# MCXN947_cm33_core0 register map
Vendor: nxp.com; File version: 1.0
CPU: CM33 r2p0, little endian, MPU, FPU, VTOR, 3 interrupt priority bits
Registers are 32-bit, read-write, reset 0x0 unless marked. A register's access mark holds for its fields unless they carry their own. Offsets are from the block's base; [hi:lo] are bit positions; {n}, {i} and the like mark numbered series.

## USBHS1__USBC — USB
Base 0x4010B000
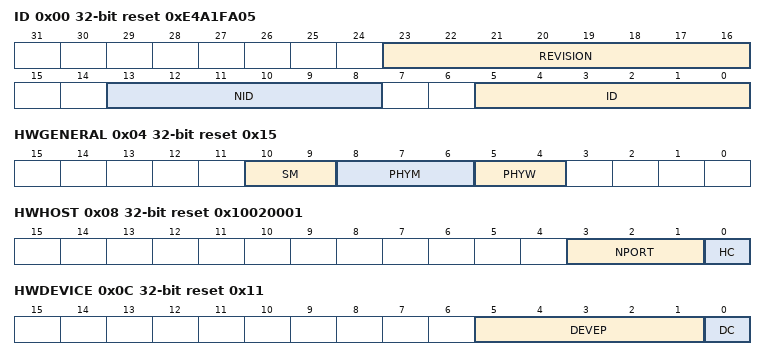
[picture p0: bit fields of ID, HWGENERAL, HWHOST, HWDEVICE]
0x00 ID ro reset 0xE4A1FA05 — Identification register
  [23:16] REVISION, [13:8] NID, [5:0] ID
0x04 HWGENERAL ro reset 0x15 — Hardware General
  [10:9] SM
    0=SERIAL_ENGINE_NO (No Serial Engine, always use parallel signalling.); 1=SERIAL_ENGINE_EN (Serial Engine present, always use serial signalling for FS/LS.); 2=SW_RST_PARALLEL (Software programmable - Reset to use parallel signalling for FS/LS); 3=SW_RST_SERIAL_ENG (Software programmable - Reset to use serial signalling for FS/LS)
  [8:6] PHYM
    0=UTMI (UTMI/UMTI+); 1=ULPI_DDR; 2=ULPI; 3=SERIAL (Serial Only); 4=SW_RST_UTMI (Software programmable - reset to UTMI/UTMI+); 5=SW_RST_ULPI_DDR (Software programmable - reset to ULPI DDR); 6=SW_RST_ULPI (Software programmable - reset to ULPI); 7=SW_RST_SERIAL (Software programmable - reset to Serial)
  [5:4] PHYW
    0=DATA_BUS_8 (8 bit wide data bus (Software non-programmable)); 1=DATA_BUS_16 (16 bit wide data bus (Software non-programmable)); 2=SW_RST_8 (Reset to 8 bit wide data bus (Software programmable)); 3=SW_RST_16 (Reset to 16 bit wide data bus (Software programmable))
0x08 HWHOST ro reset 0x10020001 — Host Hardware Parameters
  [3:1] NPORT
  [0] HC
    0=HOST_OP_DIS (Not supported); 1=HOST_OP_EN (Supported)
0x0C HWDEVICE ro reset 0x11 — Device Hardware Parameters
  [5:1] DEVEP
  [0] DC
    0=DEVICE_OP_DIS (Not supported); 1=DEVICE_OP_EN (Supported)
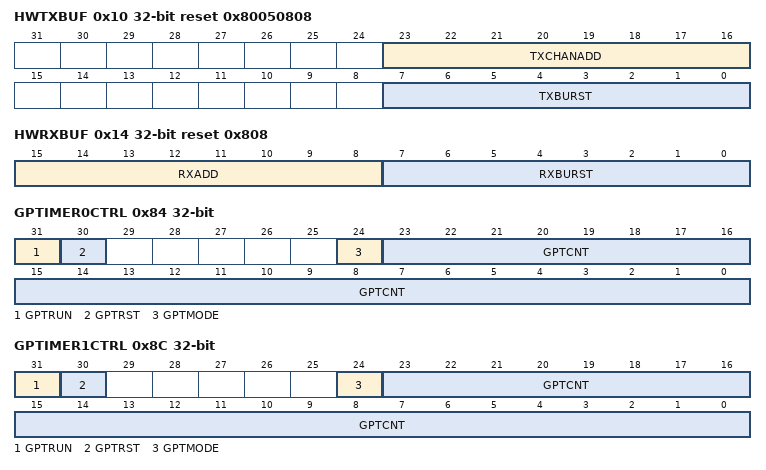
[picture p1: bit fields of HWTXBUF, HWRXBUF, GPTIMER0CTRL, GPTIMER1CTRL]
0x10 HWTXBUF ro reset 0x80050808 — TX Buffer Hardware Parameters
  [23:16] TXCHANADD, [7:0] TXBURST
0x14 HWRXBUF ro reset 0x808 — RX Buffer Hardware Parameters
  [15:8] RXADD, [7:0] RXBURST
0x80 GPTIMER0LD — General Purpose Timer #0 Load
  [23:0] GPTLD
0x84 GPTIMER0CTRL — General Purpose Timer #0 Controller
  [31] GPTRUN
    0=STOP_CNTR (Stop counting); 1=RUN
  [30] GPTRST wo
    0=NO_ACTION; 1=LOAD_CNTR (Load counter value from GPTLD bits in n_GPTIMER0LD)
  [24] GPTMODE
    0=ONE_SHOT (One Shot Mode); 1=REPEAT (Repeat Mode)
  [23:0] GPTCNT ro
0x88 GPTIMER1LD — General Purpose Timer #1 Load
  [23:0] GPTLD
0x8C GPTIMER1CTRL — General Purpose Timer #1 Controller
  [31] GPTRUN
    0=STOP_CNTR (Stop counting); 1=RUN
  [30] GPTRST wo
    0=NO_ACTION; 1=LOAD_CNTR (Load counter value from GPTLD bits in USB_n_GPTIMER0LD)
  [24] GPTMODE
    0=ONE_SHOT (One Shot Mode); 1=REPEAT (Repeat Mode)
  [23:0] GPTCNT ro
0x90 SBUSCFG reset 0x2 — System Bus Config
  [2:0] AHBBRST
    0=INCR_BURST (Incremental burst of unspecified length only); 1=INCR4_BURST (INCR4 burst, then single transfer); 2=INCR8_BURST (INCR8 burst, INCR4 burst, then single transfer); 3=INCR16_BURST (INCR16 burst, INCR8 burst, INCR4 burst, then single transfer); 5=INCR4_UNSPEC (INCR4 burst, then incremental burst of unspecified length); 6=INCR8_4_UNSPEC (INCR8 burst, INCR4 burst, then incremental burst of unspecified length); 7=INCR16_8_4_UNSPEC (INCR16 burst, INCR8 burst, INCR4 burst, then incremental burst of unspecified length)
0x100 CAPLENGTH 8-bit ro reset 0x40 — Capability Registers Length
0x102 HCIVERSION 16-bit ro reset 0x100 — Host Controller Interface Version
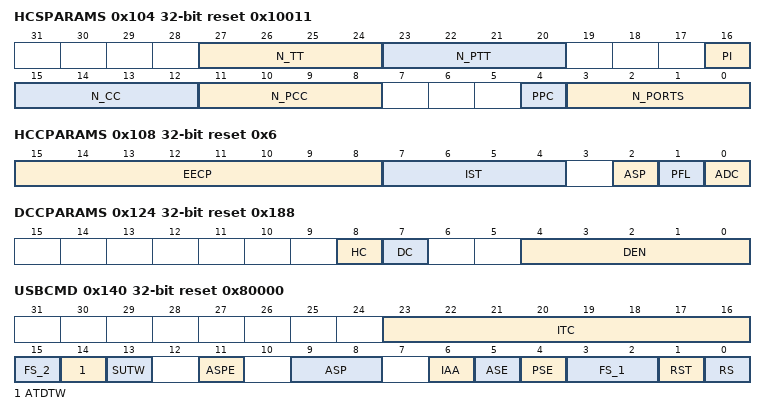
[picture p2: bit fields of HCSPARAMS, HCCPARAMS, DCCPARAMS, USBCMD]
0x104 HCSPARAMS ro reset 0x10011 — Host Controller Structural Parameters
  [27:24] N_TT
  [23:20] N_PTT
  [16] PI
  [15:12] N_CC
    0=NO_COMP_CONTROLLER (There is no internal Companion Controller and port-ownership hand-off is not supported.); 1=COMP_CONTROLLER (There are internal companion controller(s) and port-ownership hand-offs is supported.)
  [11:8] N_PCC
  [4] PPC
  [3:0] N_PORTS
0x108 HCCPARAMS ro reset 0x6 — Host Controller Capability Parameters
  [15:8] EECP, [7:4] IST, [2] ASP, [1] PFL, [0] ADC
0x120 DCIVERSION 16-bit ro reset 0x1 — Device Controller Interface Version
0x124 DCCPARAMS ro reset 0x188 — Device Controller Capability Parameters
  [8] HC, [7] DC, [4:0] DEN
0x140 USBCMD reset 0x80000 — USB Command Register
  [23:16] ITC
    0=IMMEDIATE (Immediate (no threshold)); 1=MICROFRAME_1 (1 micro-frame); 2=MICROFRAME_2 (2 micro-frames); 4=MICROFRAME_4 (4 micro-frames); 8=MICROFRAME_8 (8 micro-frames); 16=MICROFRAME_16 (16 micro-frames); 32=MICROFRAME_32 (32 micro-frames); 64=MICROFRAME_64 (64 micro-frames)
  [15] FS_2
  [14] ATDTW
  [13] SUTW
  [11] ASPE
  [9:8] ASP
  [6] IAA
  [5] ASE
    0=DONT_PROCESS_ASYNC (Do not process the Asynchronous Schedule.); 1=ACCESS_ASYNC (Use the ASYNCLISTADDR register to access the Asynchronous Schedule.)
  [4] PSE
    0=DONT_PROCESS_PT (Do not process the Periodic Schedule); 1=PROCESS_PT_PERIODICLISTBASE (Use the PERIODICLISTBASE register to access the Periodic Schedule.)
  [3:2] FS_1
  [1] RST
  [0] RS
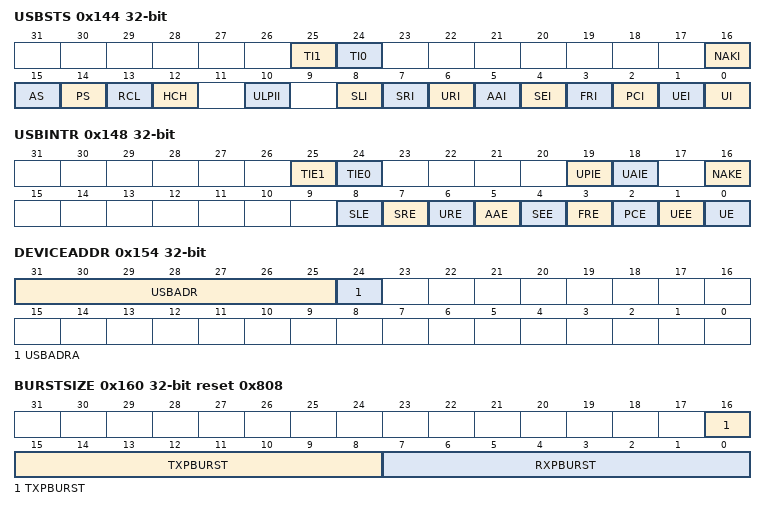
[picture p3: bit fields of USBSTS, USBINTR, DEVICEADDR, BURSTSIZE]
0x144 USBSTS (reset mask 0xFFFFFF7F) — USB Status Register
  [25] TI1 write-1-clears, [24] TI0 write-1-clears, [16] NAKI ro, [15] AS ro, [14] PS ro, [13] RCL ro, [12] HCH ro, [10] ULPII write-1-clears, [8] SLI write-1-clears, [7] SRI write-1-clears, [6] URI write-1-clears, [5] AAI write-1-clears, [4] SEI write-1-clears, [3] FRI write-1-clears, [2] PCI write-1-clears, [1] UEI write-1-clears, [0] UI write-1-clears
0x148 USBINTR — Interrupt Enable Register
  [25] TIE1, [24] TIE0, [19] UPIE, [18] UAIE, [16] NAKE, [8] SLE, [7] SRE, [6] URE, [5] AAE, [4] SEE, [3] FRE, [2] PCE, [1] UEE, [0] UE
0x14C FRINDEX — USB Frame Index
  [13:0] FRINDEX
    0=(1024) 12; 1=(512) 11; 2=(256) 10; 3=(128) 9; 4=(64) 8; 5=(32) 7; 6=(16) 6; 7=(8) 5
0x154 DEVICEADDR (ADDRESS_MODES view) — Device Address
  [31:25] USBADR, [24] USBADRA
0x154 PERIODICLISTBASE (ADDRESS_MODES view) — Frame List Base Address
  [31:12] BASEADR
0x158 ASYNCLISTADDR (ADDRESS_MODES view) — Next Asynch. Address
  [31:5] ASYBASE
0x158 ENDPTLISTADDR (ADDRESS_MODES view) — Endpoint List Address
  [31:11] EPBASE
0x160 BURSTSIZE reset 0x808 — Programmable Burst Size
  [16:8] TXPBURST, [7:0] RXPBURST
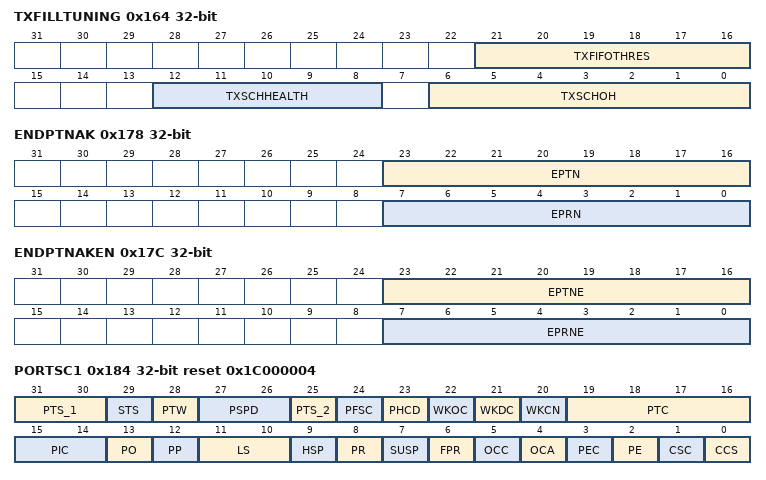
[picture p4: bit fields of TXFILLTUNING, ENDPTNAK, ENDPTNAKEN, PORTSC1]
0x164 TXFILLTUNING — TX FIFO Fill Tuning
  [21:16] TXFIFOTHRES, [12:8] TXSCHHEALTH, [6:0] TXSCHOH
0x178 ENDPTNAK write-1-clears — Endpoint NAK
  [23:16] EPTN write-1-clears, [7:0] EPRN write-1-clears
0x17C ENDPTNAKEN — Endpoint NAK Enable
  [23:16] EPTNE, [7:0] EPRNE
0x180 CONFIGFLAG ro reset 0x1 — Configure Flag Register
  [0] CF
    0=PORT_ROUTING_CLASSIC_HOST (Port routing control logic default-routes each port to an implementation dependent classic host controller.); 1=PORT_ROUTING_HOST (Port routing control logic default-routes all ports to this host controller.)
0x184 PORTSC1 reset 0x1C000004 — Port Status & Control
  [31:30] PTS_1 ro
  [29] STS ro
  [28] PTW ro
    0=UTMI_8 (Select the 8-bit UTMI interface [60MHz]); 1=UTMI_16 (Select the 16-bit UTMI interface [30MHz])
  [27:26] PSPD
    0=FS (Full Speed); 1=LS (Low Speed); 2=HS (High Speed); 3=UNDEFINED
  [25] PTS_2 ro
  [24] PFSC
    0=NORMAL (Normal operation); 1=FULL_SPEED (Forced to full speed)
  [23] PHCD
    0=PHY_CLK_EN (Enable PHY clock); 1=PHY_CLK_DIS (Disable PHY clock)
  [22] WKOC
  [21] WKDC
  [20] WKCN
  [19:16] PTC
    0=TST_MODE_DIS (TEST_MODE_DISABLE); 1=J_STATE; 2=K_STATE; 3=SE0 (SE0 (host) / NAK (device)); 4=PCKT (Packet); 5=HS (FORCE_ENABLE_HS); 6=FS (FORCE_ENABLE_FS); 7=LS (FORCE_ENABLE_LS)
  [15:14] PIC
    0=PORT_INDICATOR_OFF (Port indicators are off); 1=PORT_IND_AMBER (Amber); 2=PORT_IND_GREEN (Green); 3=UNDEFINED
  [13] PO ro
  [12] PP
  [11:10] LS ro
    0=SE0; 1=K_STATE; 2=J_STATE; 3=UNDEFINED
  [9] HSP ro
  [8] PR
  [7] SUSP
  [6] FPR
  [5] OCC write-1-clears
  [4] OCA ro
    0=NO_OVERCURRENT (This port does not have an over-current condition.); 1=OVERCURRENT (This port currently has an over-current condition)
  [3] PEC write-1-clears
  [2] PE
  [1] CSC write-1-clears
  [0] CCS ro
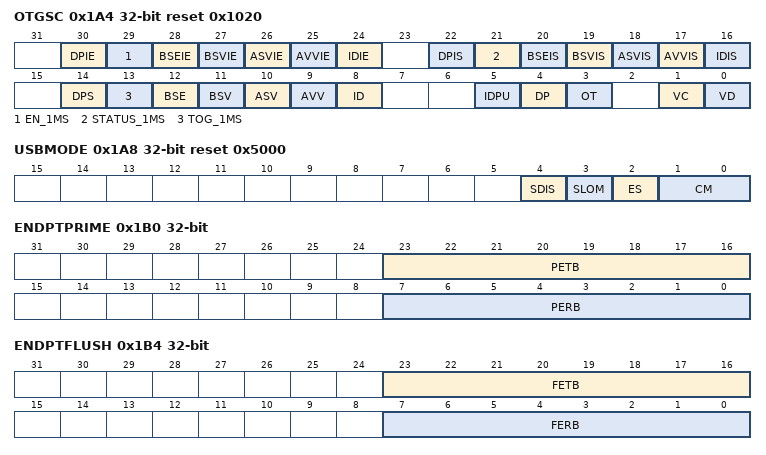
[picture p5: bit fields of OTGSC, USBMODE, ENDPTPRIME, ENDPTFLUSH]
0x1A4 OTGSC reset 0x1020 (reset mask 0xFFDFDDFF) — On-The-Go Status & control
  [30] DPIE, [29] EN_1MS, [28] BSEIE, [27] BSVIE, [26] ASVIE, [25] AVVIE, [24] IDIE, [22] DPIS, [21] STATUS_1MS, [20] BSEIS, [19] BSVIS, [18] ASVIS, [17] AVVIS, [16] IDIS, [14] DPS ro, [13] TOG_1MS ro, [12] BSE ro, [11] BSV ro, [10] ASV ro, [9] AVV ro, [8] ID ro, [5] IDPU, [4] DP, [3] OT, [1] VC, [0] VD
0x1A8 USBMODE reset 0x5000 — USB Device Mode
  [4] SDIS
  [3] SLOM
    0=LOCKOUT_ON (Setup Lockouts On (default);); 1=LOCKOUT_OFF (Setup Lockouts Off)
  [2] ES
    0=LITTLE_ENDIAN (Little Endian [Default]); 1=BIG_ENDIAN
  [1:0] CM
    0=IDL (Idle [Default for combination host/device]); 2=DEVICE_CONTR (Device Controller [Default for device only controller]); 3=HOST_CONTR (Host Controller [Default for host only controller])
0x1AC ENDPTSETUPSTAT write-1-clears — Endpoint Setup Status
  [15:0] ENDPTSETUPSTAT write-1-clears
0x1B0 ENDPTPRIME — Endpoint Prime
  [23:16] PETB, [7:0] PERB
0x1B4 ENDPTFLUSH — Endpoint Flush
  [23:16] FETB, [7:0] FERB
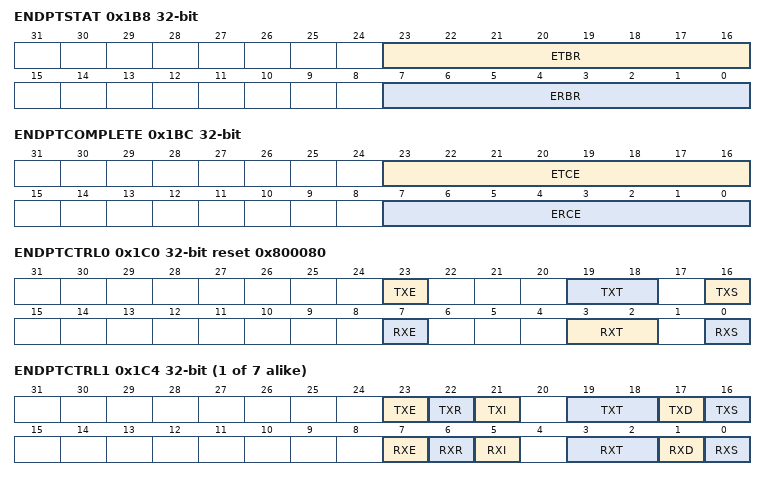
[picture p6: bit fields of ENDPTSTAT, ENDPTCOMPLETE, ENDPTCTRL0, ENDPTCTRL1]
0x1B8 ENDPTSTAT ro — Endpoint Status
  [23:16] ETBR, [7:0] ERBR
0x1BC ENDPTCOMPLETE write-1-clears — Endpoint Complete
  [23:16] ETCE write-1-clears, [7:0] ERCE write-1-clears
0x1C0 ENDPTCTRL0 reset 0x800080 — Endpoint Control0
  [23] TXE ro, [19:18] TXT ro, [16] TXS, [7] RXE ro, [3:2] RXT ro, [0] RXS
{0x1C0+4i} ENDPTCTRL{i} (i=1..7) — Endpoint Control {i}
  [23] TXE, [22] TXR wo, [21] TXI, [19:18] TXT, [17] TXD, [16] TXS, [7] RXE, [6] RXR wo, [5] RXI, [3:2] RXT, [1] RXD, [0] RXS
